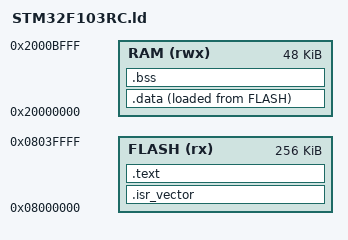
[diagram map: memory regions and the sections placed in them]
/* STM32F103RC 链接脚本 (HD: 256KB Flash / 48KB RAM) */
ENTRY(Reset_Handler)

_estack = 0x2000C000;   /* RAM 末尾 */

MEMORY
{
  FLASH (rx)  : ORIGIN = 0x08000000, LENGTH = 256K
  RAM   (rwx) : ORIGIN = 0x20000000, LENGTH = 48K
}

SECTIONS
{
  .isr_vector :
  {
    . = ALIGN(4);
    KEEP(*(.isr_vector))
    . = ALIGN(4);
  } >FLASH

  .text :
  {
    . = ALIGN(4);
    *(.text)
    *(.text.*)
    *(.rodata)
    *(.rodata.*)
    . = ALIGN(4);
    _etext = .;
  } >FLASH

  _sidata = LOADADDR(.data);

  .data :
  {
    . = ALIGN(4);
    _sdata = .;
    *(.data)
    *(.data.*)
    . = ALIGN(4);
    _edata = .;
  } >RAM AT> FLASH

  .bss :
  {
    . = ALIGN(4);
    _sbss = .;
    *(.bss)
    *(.bss.*)
    *(COMMON)
    . = ALIGN(4);
    _ebss = .;
  } >RAM

  . = ALIGN(4);
  _end = .;
}
